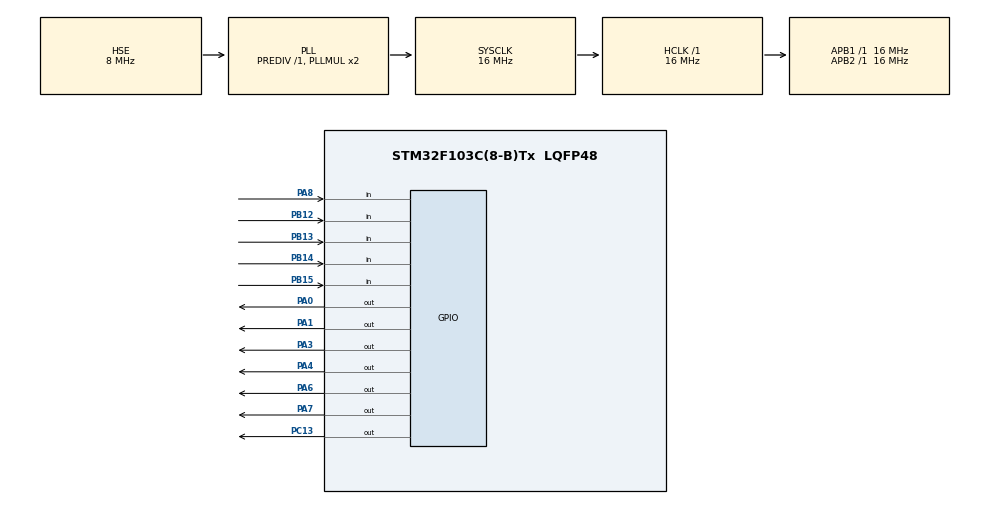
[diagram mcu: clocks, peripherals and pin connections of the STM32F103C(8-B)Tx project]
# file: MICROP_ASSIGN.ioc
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Mcu.Family=STM32F1
Mcu.Name=STM32F103C(8-B)Tx
Mcu.Package=LQFP48
NVIC.PriorityGroup=NVIC_PRIORITYGROUP_4
PA0-WKUP.Signal=GPIO_Output
PA1.Signal=GPIO_Output
PA3.Signal=GPIO_Output
PA4.Signal=GPIO_Output
PA6.Signal=GPIO_Output
PA7.Signal=GPIO_Output
PA8.Signal=GPIO_Input
PB12.Signal=GPIO_Input
PB13.Signal=GPIO_Input
PB14.Signal=GPIO_Input
PB15.Signal=GPIO_Input
PC13-TAMPER-RTC.Signal=GPIO_Output
PD0-OSC_IN.Mode=HSE-External-Oscillator
PD0-OSC_IN.Signal=RCC_OSC_IN
PD1-OSC_OUT.Mode=HSE-External-Oscillator
PD1-OSC_OUT.Signal=RCC_OSC_OUT
ProjectManager.HeapSize=0x200
ProjectManager.StackSize=0x400
ProjectManager.TargetToolchain=STM32CubeIDE
RCC.AHBFreq_Value=16000000
RCC.APB1Freq_Value=16000000
RCC.APB1TimFreq_Value=16000000
RCC.APB2Freq_Value=16000000
RCC.APB2TimFreq_Value=16000000
RCC.HCLKFreq_Value=16000000
RCC.PLLSourceVirtual=RCC_PLLSOURCE_HSE
RCC.SYSCLKFreq_VALUE=16000000
RCC.SYSCLKSource=RCC_SYSCLKSOURCE_PLLCLK
RCC.USBFreq_Value=16000000
VP_SYS_VS_ND.Mode=No_Debug
board=custom

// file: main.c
/* USER CODE BEGIN Header */
/**
  ******************************************************************************
  * @file           : main.c
  * @brief          : Main program body
  ******************************************************************************
  * @attention
  *
  * <h2><center>&copy; Copyright (c) 2022 STMicroelectronics.
  * All rights reserved.</center></h2>
  *
  * This software component is licensed by ST under BSD 3-Clause license,
  * the "License"; You may not use this file except in compliance with the
  * License. You may obtain a copy of the License at:
  *                        opensource.org/licenses/BSD-3-Clause
  *
  ******************************************************************************
  */
/* USER CODE END Header */
#include "main.h"

/* USER CODE BEGIN PV */
int flag;
int d1, d2, d3, d4;
int s;
/* USER CODE END PV */

void SystemClock_Config(void);
static void MX_GPIO_Init(void);

void long_press (void);
void short_press (void);

void  knightrider (int speed)
{
	  HAL_GPIO_WritePin(GPIOA, GPIO_PIN_7, 1);
	  HAL_GPIO_WritePin(GPIOA, GPIO_PIN_6, 0);
	  HAL_Delay(speed);
	  HAL_GPIO_WritePin(GPIOA, GPIO_PIN_7, 1);
	  HAL_GPIO_WritePin(GPIOA, GPIO_PIN_6, 1);
	  HAL_Delay(speed);
	  HAL_GPIO_WritePin(GPIOA, GPIO_PIN_7, 0);
	  HAL_GPIO_WritePin(GPIOA, GPIO_PIN_6, 1);
	  HAL_GPIO_WritePin(GPIOA, GPIO_PIN_4, 1);
	  HAL_Delay(speed);
	  HAL_GPIO_WritePin(GPIOA, GPIO_PIN_6, 0);
	  HAL_GPIO_WritePin(GPIOA, GPIO_PIN_4, 1);
	  HAL_GPIO_WritePin(GPIOA, GPIO_PIN_3, 1);
	  HAL_Delay(speed);
	  HAL_GPIO_WritePin(GPIOA, GPIO_PIN_4, 0);
	  HAL_GPIO_WritePin(GPIOA, GPIO_PIN_3, 1);
	  HAL_GPIO_WritePin(GPIOA, GPIO_PIN_1, 1);
	  HAL_Delay(speed);
	  HAL_GPIO_WritePin(GPIOA, GPIO_PIN_3, 0);
	  HAL_GPIO_WritePin(GPIOA, GPIO_PIN_1, 1);
	  HAL_GPIO_WritePin(GPIOA, GPIO_PIN_0, 1);
	  HAL_Delay(speed);
	  HAL_GPIO_WritePin(GPIOA, GPIO_PIN_1, 0);
	  HAL_GPIO_WritePin(GPIOA, GPIO_PIN_0, 1);
	  HAL_Delay(speed);
	  HAL_GPIO_WritePin(GPIOA, GPIO_PIN_0, 1);
	  HAL_GPIO_WritePin(GPIOA, GPIO_PIN_1, 1);
	  HAL_Delay(speed);
	  HAL_GPIO_WritePin(GPIOA, GPIO_PIN_3, 1);
	  HAL_GPIO_WritePin(GPIOA, GPIO_PIN_1, 1);
	  HAL_GPIO_WritePin(GPIOA, GPIO_PIN_0, 0);
	  HAL_Delay(speed);
	  HAL_GPIO_WritePin(GPIOA, GPIO_PIN_4, 1);
	  HAL_GPIO_WritePin(GPIOA, GPIO_PIN_3, 1);
	  HAL_GPIO_WritePin(GPIOA, GPIO_PIN_1, 0);
	  HAL_Delay(speed);
	  HAL_GPIO_WritePin(GPIOA, GPIO_PIN_6, 1);
	  HAL_GPIO_WritePin(GPIOA, GPIO_PIN_4, 1);
	  HAL_GPIO_WritePin(GPIOA, GPIO_PIN_3, 0);
	  HAL_Delay(speed);
	  HAL_GPIO_WritePin(GPIOA, GPIO_PIN_7, 1);
	  HAL_GPIO_WritePin(GPIOA, GPIO_PIN_6, 1);
	  HAL_GPIO_WritePin(GPIOA, GPIO_PIN_4, 0);
	  HAL_Delay(speed);
//	  flag = flag - 1;
}

int main(void)
{

  /* MCU Configuration--------------------------------------------------------*/

  /* Reset of all peripherals, Initializes the Flash interface and the Systick. */
  HAL_Init();

  /* Configure the system clock */
  SystemClock_Config();

  /* Initialize all configured peripherals */
  MX_GPIO_Init();

  /* Infinite loop */
  /* USER CODE BEGIN WHILE */
  while (1)
  {
//	  s = 250;
    /* USER CODE END WHILE */
	  if(HAL_GPIO_ReadPin(GPIOB, GPIO_PIN_9) == 0) {

	  if (HAL_GPIO_ReadPin(GPIOB, GPIO_PIN_12) == 0){
		  if(HAL_GPIO_ReadPin(GPIOA, GPIO_PIN_8) == 1){
			  d4 = 0;
		  }
		  else{
			  d4 = 8;
		  }

		  if(HAL_GPIO_ReadPin(GPIOB, GPIO_PIN_15) == 1){
			  d3 = 0;
		  }
		  else{
			  d3 = 4;
		  }

		  if(HAL_GPIO_ReadPin(GPIOB, GPIO_PIN_14) == 1){
			  d2 = 0;
		  }
		  else{
			  d2 = 2;
		  }

		  if(HAL_GPIO_ReadPin(GPIOB, GPIO_PIN_13) == 1){
			  d1 = 0;
		  }
		  else{
			  d1 = 1;
		  }

		  s = (int) 100 * (d1 + d2 + d3 + d4 + 1);
//		  s = 250;
		  flag = 2;
	  }
	  else {
		  s = s;
	  }

	  if(flag == 2){
		  knightrider(s);
	  }
	  }

	  else {
	  // 1.1
//	  HAL_GPIO_TogglePin(GPIOC, GPIO_PIN_13);
//	  HAL_Delay(200);

	  // 1.2
	  // Z
	  long_press();
	  long_press();
	  short_press();

	  HAL_Delay(2000);
	  // T
	  short_press();
	  long_press();
	  short_press();

	  HAL_Delay(2000);
	  // L
	  long_press();
	  short_press();
	  short_press();

	  HAL_Delay(2000);
	  }

//	  knightrider(s);
  }
}

void SystemClock_Config(void)
{
  RCC_OscInitTypeDef RCC_OscInitStruct = {0};
  RCC_ClkInitTypeDef RCC_ClkInitStruct = {0};

  /** Initializes the RCC Oscillators according to the specified parameters
  * in the RCC_OscInitTypeDef structure.
  */
  RCC_OscInitStruct.OscillatorType = RCC_OSCILLATORTYPE_HSE;
  RCC_OscInitStruct.HSEState = RCC_HSE_ON;
  RCC_OscInitStruct.HSEPredivValue = RCC_HSE_PREDIV_DIV1;
  RCC_OscInitStruct.HSIState = RCC_HSI_ON;
  RCC_OscInitStruct.PLL.PLLState = RCC_PLL_ON;
  RCC_OscInitStruct.PLL.PLLSource = RCC_PLLSOURCE_HSE;
  RCC_OscInitStruct.PLL.PLLMUL = RCC_PLL_MUL2;
  if (HAL_RCC_OscConfig(&RCC_OscInitStruct) != HAL_OK)
  {
    Error_Handler();
  }
  /** Initializes the CPU, AHB and APB buses clocks
  */
  RCC_ClkInitStruct.ClockType = RCC_CLOCKTYPE_HCLK|RCC_CLOCKTYPE_SYSCLK
                              |RCC_CLOCKTYPE_PCLK1|RCC_CLOCKTYPE_PCLK2;
  RCC_ClkInitStruct.SYSCLKSource = RCC_SYSCLKSOURCE_PLLCLK;
  RCC_ClkInitStruct.AHBCLKDivider = RCC_SYSCLK_DIV1;
  RCC_ClkInitStruct.APB1CLKDivider = RCC_HCLK_DIV1;
  RCC_ClkInitStruct.APB2CLKDivider = RCC_HCLK_DIV1;

  if (HAL_RCC_ClockConfig(&RCC_ClkInitStruct, FLASH_LATENCY_0) != HAL_OK)
  {
    Error_Handler();
  }
}

static void MX_GPIO_Init(void)
{
  GPIO_InitTypeDef GPIO_InitStruct = {0};

  /* GPIO Ports Clock Enable */
  __HAL_RCC_GPIOC_CLK_ENABLE();
  __HAL_RCC_GPIOD_CLK_ENABLE();
  __HAL_RCC_GPIOA_CLK_ENABLE();
  __HAL_RCC_GPIOB_CLK_ENABLE();

  /*Configure GPIO pin Output Level */
  HAL_GPIO_WritePin(GPIOC, GPIO_PIN_13, GPIO_PIN_RESET);

  /*Configure GPIO pin Output Level */
  HAL_GPIO_WritePin(GPIOA, GPIO_PIN_0|GPIO_PIN_1|GPIO_PIN_3|GPIO_PIN_4
                          |GPIO_PIN_6|GPIO_PIN_7, GPIO_PIN_RESET);

  /*Configure GPIO pin : PC13 */
  GPIO_InitStruct.Pin = GPIO_PIN_13;
  GPIO_InitStruct.Mode = GPIO_MODE_OUTPUT_PP;
  GPIO_InitStruct.Pull = GPIO_NOPULL;
  GPIO_InitStruct.Speed = GPIO_SPEED_FREQ_LOW;
  HAL_GPIO_Init(GPIOC, &GPIO_InitStruct);

  /*Configure GPIO pins : PA0 PA1 PA3 PA4
                           PA6 PA7 */
  GPIO_InitStruct.Pin = GPIO_PIN_0|GPIO_PIN_1|GPIO_PIN_3|GPIO_PIN_4
                          |GPIO_PIN_6|GPIO_PIN_7;
  GPIO_InitStruct.Mode = GPIO_MODE_OUTPUT_PP;
  GPIO_InitStruct.Pull = GPIO_NOPULL;
  GPIO_InitStruct.Speed = GPIO_SPEED_FREQ_LOW;
  HAL_GPIO_Init(GPIOA, &GPIO_InitStruct);

  /*Configure GPIO pins : PB12 PB13 PB14 PB15 */
  GPIO_InitStruct.Pin = GPIO_PIN_12|GPIO_PIN_12|GPIO_PIN_13|GPIO_PIN_14|GPIO_PIN_15;
  GPIO_InitStruct.Mode = GPIO_MODE_INPUT;
  GPIO_InitStruct.Pull = GPIO_NOPULL;
  HAL_GPIO_Init(GPIOB, &GPIO_InitStruct);

  /*Configure GPIO pin : PA8 */
  GPIO_InitStruct.Pin = GPIO_PIN_8;
  GPIO_InitStruct.Mode = GPIO_MODE_INPUT;
  GPIO_InitStruct.Pull = GPIO_NOPULL;
  HAL_GPIO_Init(GPIOA, &GPIO_InitStruct);

}

/* USER CODE BEGIN 4 */
void long_press (void)
{
	HAL_Delay(1000);

	HAL_GPIO_WritePin(GPIOC, GPIO_PIN_13, 0);
	HAL_Delay(1200);
	HAL_GPIO_WritePin(GPIOC, GPIO_PIN_13, 1);
}
/* USER CODE END 4 */

void short_press (void)
{
	HAL_Delay(1000);

	HAL_GPIO_WritePin(GPIOC, GPIO_PIN_13, 0);
	HAL_Delay(400);
	HAL_GPIO_WritePin(GPIOC, GPIO_PIN_13, 1);
}

void Error_Handler(void)
{
}

/************************ (C) COPYRIGHT STMicroelectronics *****END OF FILE****/
